# netx90_app register map
File version: 1.0
CPU: CM4 r0p1, little endian, MPU, FPU, 4 interrupt priority bits, 78 interrupts
Registers are 32-bit, read-write, reset 0x0 unless marked. A register's access mark holds for its fields unless they carry their own. Offsets are from the block's base; [hi:lo] are bit positions; {n}, {i} and the like mark numbered series; 'fields as' and 'values as' point back to an identical list.

## nfifo
Base 0xFF400000
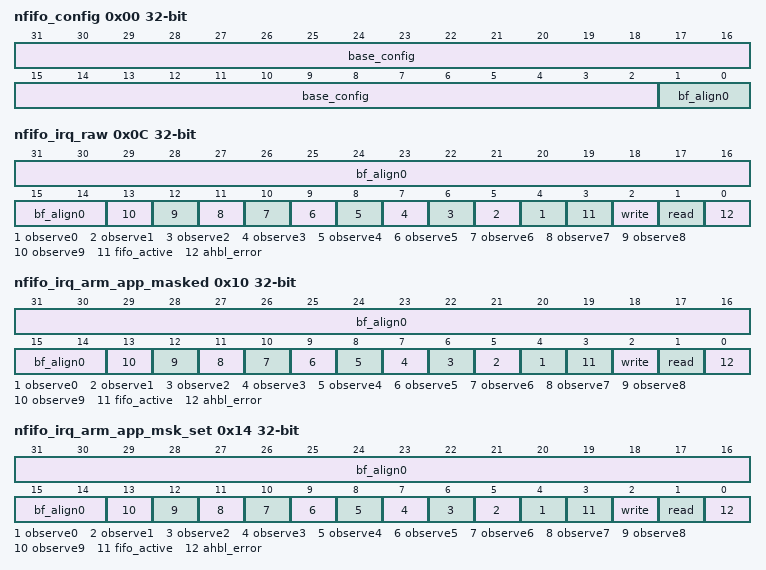
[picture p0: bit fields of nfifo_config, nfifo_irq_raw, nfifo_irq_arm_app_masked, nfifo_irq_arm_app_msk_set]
0x00 nfifo_config (reset mask 0xFFFFFFFC) — NFIFO config register 'base_config' is a pointer to start of NFIFO configuration area in memory. The configuration area must be setup by software, before using a FIFO. Each FIFO-configuration entry consists of 3 DW and contains the following: { | mem-DW0: base(31:2),mas(1:0) mem-DW1: watm(28:16),bottom(12:0) mem-DW2: undr(31),emw(30),empty(29),write(28:16),ovfl(15),fmw(14),full(13),fill(12:0) } This allows FIFOs of up to 8k entries each. The first DWords mem-DW0 and mem-DW1 are only read by NFIFO controller. To reset a FIFO, reinit the configuration entries mem-DW0..2.
  [31:2] base_config — Pointer to base_config
  [1:0] bf_align0 — bitField alignment value for aeabi compatibility
0x0C nfifo_irq_raw (reset mask 0x3FFF) — Raw IRQ: Read access shows status of unmasked IRQs. IRQs are set automatically and reset by writing to this register: Write access with '1' resets the appropriate IRQ. Write access with '0' does not influence this bit.
  [31:14] bf_align0 — bitField alignment value for aeabi compatibility
  [n+4] observe{n} (n=0..9) — access to FIFO as defined in observe{n}
  [3] fifo_active — any access to fifo_nr/fifo_wr is active (to unlock the scheduler after locking_req)
  [2] write — any write access happened to any FIFO
  [1] read — any read access happened to any FIFO
  [0] ahbl_error — AHBL returned HRESP=1 (abort)
0x10 nfifo_irq_arm_app_masked ro (reset mask 0x3FFF) — Masked IRQ of ARM_APP: Shows status of masked IRQs as connected to application ARM Cortex M4.
  fields as nfifo_irq_raw
0x14 nfifo_irq_arm_app_msk_set (reset mask 0x3FFF) — ARM_APP Cortex M4 IRQ mask set: The IRQ mask enables interrupt requests for corresponding interrupt sources to the ARM_APP processor. As its bits might be changed by different software tasks, the IRQ mask register is not writable directly, but by set and reset masks: Write access with '1' sets interrupt mask bit. Write access with '0' does not influence this bit. Read access shows actual interrupt mask. Attention: Before activating interrupt mask, delete old pending interrupts by writing the same value to adr_nfifo_irq_raw.
  fields as nfifo_irq_raw
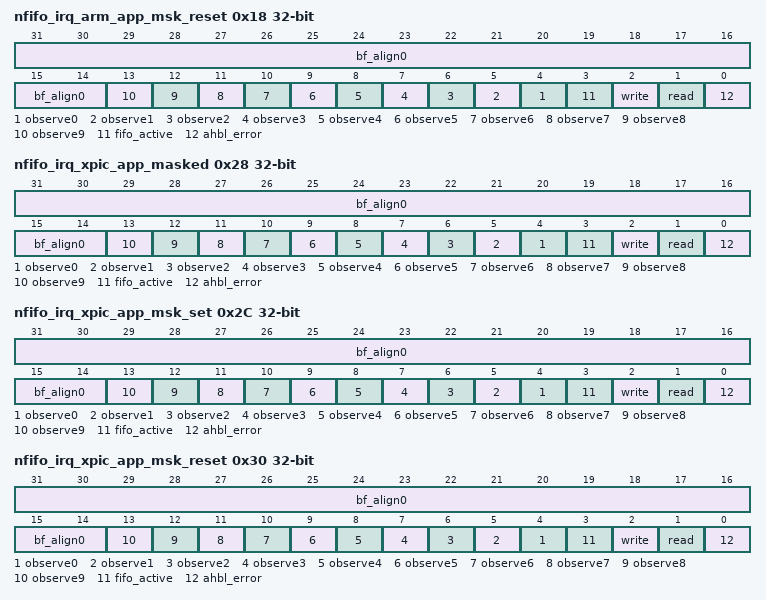
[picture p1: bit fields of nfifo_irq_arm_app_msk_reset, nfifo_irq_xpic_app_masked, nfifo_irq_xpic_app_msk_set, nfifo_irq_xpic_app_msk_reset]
0x18 nfifo_irq_arm_app_msk_reset (reset mask 0x3FFF) — ARM_APP Cortex M4 IRQ mask reset: This is the corresponding reset mask to disable interrupt requests for corresponding interrupt sources: Write access with '1' resets interrupt mask bit. Write access with '0' does not influence this bit. Read access shows actual interrupt mask.
  fields as nfifo_irq_raw
0x28 nfifo_irq_xpic_app_masked ro (reset mask 0x3FFF) — Masked IRQ of xPIC_APP: Shows status of masked IRQs as connected to xPIC_APP.
  fields as nfifo_irq_raw
0x2C nfifo_irq_xpic_app_msk_set (reset mask 0x3FFF) — xPIC_APP IRQ mask set: The xPIC_APP IRQ mask enables interrupt requests for corresponding interrupt sources to the xPIC_APP processor. As its bits might be changed by different software tasks, the IRQ mask register is not writable directly, but by set and reset masks: Write access with '1' sets interrupt mask bit. Write access with '0' does not influence this bit. Read access shows actual interrupt mask. Attention: Before activating interrupt mask, delete old pending interrupts by writing the same value to adr_nfifo_irq_raw.
  fields as nfifo_irq_raw
0x30 nfifo_irq_xpic_app_msk_reset (reset mask 0x3FFF) — xPIC_APP IRQ mask reset: This is the corresponding reset mask to disable interrupt requests for corresponding interrupt sources: Write access with '1' resets interrupt mask bit. Write access with '0' does not influence this bit. Read access shows actual interrupt mask.
  fields as nfifo_irq_raw
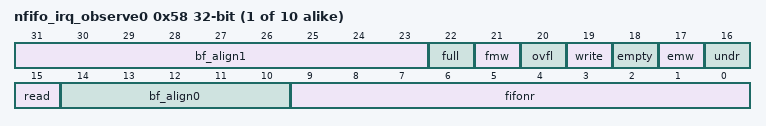
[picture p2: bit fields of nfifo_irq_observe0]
{0x58+4i} nfifo_irq_observe{i} (reset mask 0x7F83FF) (i=0..9) — FIFO OBSERVE{i}: This register configures the observation unit that allows to observe one FIFO for special events
  [31:23] bf_align1 — bitField alignment value for aeabi compatibility
  [22] full — Activate IRQ in case of FIFO gets full
  [21] fmw — Activate IRQ in case of Full-Minus-Watermark is set
  [20] ovfl — Activate IRQ in case of FIFO overflow
  [19] write — Activate IRQ in case of any write access
  [18] empty — Activate IRQ in case of FIFO gets empty
  [17] emw — Activate IRQ in case of Empty-Minus-Watermark is set
  [16] undr — Activate IRQ in case of FIFO underrun
  [15] read — Activate IRQ in case of any read access
  [14:10] bf_align0 — bitField alignment value for aeabi compatibility
  [9:0] fifonr — Number of FIFO to be observed
0x80 nfifo_fifo_start reset not defined — Start of NFIFO FIFO access addresses: The following DW-addresses are associated with FIFOs: Read accesses to an address in this area are reading from the appropriate FIFO, write accesses to an address in this area are writing to the appropriate FIFO. The number of FIFOs is limited by this address area to 991.
  [31:0] bf_align0 — bitField alignment value for aeabi compatibility
0xFFC nfifo_fifo_end reset not defined — End of NFIFO FIFO access addresses
  [31:0] bf_align0 — bitField alignment value for aeabi compatibility
